# LargeDummyDevice register map
File version: 1.0
Registers are 32-bit, read-write, no defined reset value unless marked. A register's access mark holds for its fields unless they carry their own. Offsets are from the block's base; [hi:lo] are bit positions.

## PERIPHERAL_29
Base 0x4001C000
0x04 REG_1 — Register 1
  [33:29] FIELD_7, [28] FIELD_6, [23:22] FIELD_4, [20] FIELD_3, [17:14] FIELD_8, [16:12] FIELD_2, [10:8] FIELD_1, [12:8] FIELD_11, [10:7] FIELD_9, [9:6] FIELD_10, [1] FIELD_5
0x08 REG_2 — Register 2
  [30:28] FIELD_7, [27:25] FIELD_5, [24:21] FIELD_1, [22:20] FIELD_11, [20:16] FIELD_3, [15:11] FIELD_10, [10:7] FIELD_4, [10:6] FIELD_2, [6:5] FIELD_13, [3] FIELD_8, [7:3] FIELD_9, [5:1] FIELD_6, [5:1] FIELD_12
0x0C REG_3 — Register 3
  [31:28] FIELD_7, [28:27] FIELD_11, [30:26] FIELD_5, [22] FIELD_1, [23:22] FIELD_3, [25:21] FIELD_6, [25:21] FIELD_15, [20] FIELD_10, [19] FIELD_14, [21:17] FIELD_13, [20:16] FIELD_12, [9:7] FIELD_4, [9:6] FIELD_8, [5:3] FIELD_9, [5:2] FIELD_2
0x10 REG_4 — Register 4
  [29] FIELD_10, [29:28] FIELD_8, [29:25] FIELD_13, [27:23] FIELD_16, [21] FIELD_2, [23:20] FIELD_3, [21:19] FIELD_15, [17] FIELD_14, [21:17] FIELD_17, [16:13] FIELD_21, [13:12] FIELD_5, [14:10] FIELD_1, [10] FIELD_7, [9:8] FIELD_19, [11:8] FIELD_20, [11:7] FIELD_6, [9:7] FIELD_22, [8:5] FIELD_9, [3] FIELD_12, [3:0] FIELD_4, [4:0] FIELD_11, [2:0] FIELD_18
0x14 REG_5 — Register 5
  [33:31] FIELD_2, [10:6] FIELD_1, [2:1] FIELD_3
0x18 REG_6 — Register 6
  [33:30] FIELD_21, [30:28] FIELD_11, [30:27] FIELD_2, [27] FIELD_7, [29:25] FIELD_4, [28:25] FIELD_13, [28:25] FIELD_17, [25:22] FIELD_27, [23:21] FIELD_8, [25:21] FIELD_14, [21:20] FIELD_10, [22:20] FIELD_12, [22:19] FIELD_3, [19:18] FIELD_18, [22:18] FIELD_23, [17:16] FIELD_31, [15:14] FIELD_6, [16:12] FIELD_19, [16:12] FIELD_24, [11] FIELD_16, [13:10] FIELD_15, [12:10] FIELD_28, [12:9] FIELD_20, [13:9] FIELD_26, [5] FIELD_25, [5] FIELD_29, [4] FIELD_1, [6:4] FIELD_9, [4] FIELD_30, [4:3] FIELD_22, [4:2] FIELD_5
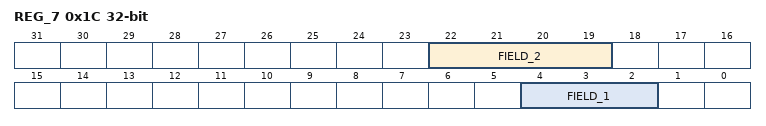
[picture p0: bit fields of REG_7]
0x1C REG_7 — Register 7
  [22:19] FIELD_2, [4:2] FIELD_1
0x20 REG_8 — Register 8
  [33:31] FIELD_10, [33:30] FIELD_16, [27] FIELD_1, [31:27] FIELD_4, [28:27] FIELD_25, [27:25] FIELD_3, [29:25] FIELD_24, [28:24] FIELD_5, [25:23] FIELD_9, [22] FIELD_6, [23:22] FIELD_17, [23:20] FIELD_15, [21:18] FIELD_14, [21:18] FIELD_23, [18:17] FIELD_11, [18:17] FIELD_21, [21:17] FIELD_22, [14:12] FIELD_8, [11] FIELD_7, [12:11] FIELD_18, [11:10] FIELD_20, [9:6] FIELD_13, [7:4] FIELD_12, [2:1] FIELD_2, [3:0] FIELD_19

## PERIPHERAL_35
Base 0x40022000
0x04 REG_1 — Register 1
  [30:29] FIELD_8, [28:27] FIELD_1, [31:27] FIELD_2, [29:27] FIELD_10, [26:25] FIELD_14, [28:24] FIELD_4, [25:23] FIELD_12, [23:20] FIELD_7, [22:20] FIELD_9, [21:18] FIELD_15, [17:14] FIELD_13, [12] FIELD_6, [13:11] FIELD_11, [6] FIELD_5, [5] FIELD_3
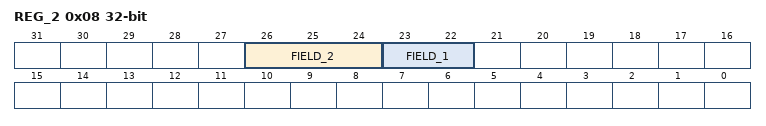
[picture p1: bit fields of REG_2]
0x08 REG_2 — Register 2
  [31:30] FIELD_8, [20:18] FIELD_2, [19:18] FIELD_5, [10:9] FIELD_4, [12:9] FIELD_11, [8] FIELD_1, [10:8] FIELD_9, [9:7] FIELD_7, [10:6] FIELD_6, [8:4] FIELD_10, [3] FIELD_3
0x0C REG_3 — Register 3
  [34:31] FIELD_3, [29] FIELD_2, [27:24] FIELD_12, [26:22] FIELD_4, [21:18] FIELD_8, [14:13] FIELD_13, [13:11] FIELD_7, [10:9] FIELD_5, [7:6] FIELD_11, [3:2] FIELD_1, [4:1] FIELD_6, [5:1] FIELD_9, [3:1] FIELD_10
0x10 REG_4 — Register 4
  [34:31] FIELD_3, [32:31] FIELD_19, [30] FIELD_4, [32:29] FIELD_10, [31:28] FIELD_18, [29:28] FIELD_20, [28:25] FIELD_17, [22] FIELD_6, [26:22] FIELD_7, [20] FIELD_5, [22:18] FIELD_9, [22:18] FIELD_12, [17] FIELD_8, [20:16] FIELD_16, [18:16] FIELD_22, [19:15] FIELD_1, [17:15] FIELD_2, [11:9] FIELD_14, [6] FIELD_13, [8:6] FIELD_21, [9:5] FIELD_15, [1] FIELD_11
0x14 REG_5 — Register 5
  [29:27] FIELD_4, [24] FIELD_5, [23:20] FIELD_8, [18] FIELD_1, [22:18] FIELD_2, [21:18] FIELD_3, [20:16] FIELD_10, [15] FIELD_7, [9] FIELD_9, [9:5] FIELD_11, [1:0] FIELD_6

## PERIPHERAL_36
Base 0x40023000
0x04 REG_1 — Register 1
  [24] FIELD_2, [28:24] FIELD_6, [23:21] FIELD_7, [14:12] FIELD_5, [8] FIELD_1, [9:7] FIELD_4, [2] FIELD_3
0x08 REG_2 — Register 2
  [26:24] FIELD_2, [23:22] FIELD_1
0x0C REG_3 — Register 3
  [33:31] FIELD_11, [33:31] FIELD_21, [30] FIELD_3, [31:30] FIELD_19, [28] FIELD_10, [32:28] FIELD_13, [30:27] FIELD_2, [30:27] FIELD_6, [25:21] FIELD_4, [22:20] FIELD_5, [24:20] FIELD_9, [22:18] FIELD_8, [13] FIELD_7, [16:13] FIELD_17, [11] FIELD_12, [10] FIELD_1, [12:10] FIELD_20, [9] FIELD_16, [6:5] FIELD_14, [8:4] FIELD_18, [6:2] FIELD_15
0x10 REG_4 — Register 4
  [31] FIELD_3, [28] FIELD_6, [31:28] FIELD_17, [28:27] FIELD_12, [28:27] FIELD_19, [27:24] FIELD_7, [26:24] FIELD_10, [28:24] FIELD_11, [27:24] FIELD_14, [23:20] FIELD_4, [21:20] FIELD_5, [18] FIELD_2, [19:16] FIELD_18, [17:15] FIELD_15, [15:13] FIELD_20, [14:11] FIELD_1, [12:11] FIELD_16, [11:9] FIELD_9, [9] FIELD_13, [9:5] FIELD_8
0x14 REG_5 — Register 5
  [32:30] FIELD_1, [29] FIELD_10, [22:18] FIELD_2, [18:16] FIELD_9, [13] FIELD_5, [13:9] FIELD_4, [11:9] FIELD_6, [10:7] FIELD_8, [9:6] FIELD_7, [1] FIELD_3
0x18 REG_6 — Register 6
  [31:28] FIELD_18, [29:28] FIELD_29, [28:27] FIELD_2, [29:27] FIELD_13, [31:27] FIELD_17, [30:26] FIELD_21, [28:25] FIELD_23, [29:25] FIELD_32, [25:23] FIELD_19, [23:22] FIELD_14, [24:22] FIELD_27, [23:20] FIELD_1, [22:20] FIELD_28, [19] FIELD_5, [20:19] FIELD_16, [19:16] FIELD_9, [16:14] FIELD_10, [16:13] FIELD_6, [15:12] FIELD_7, [12:11] FIELD_8, [14:11] FIELD_24, [14:11] FIELD_26, [12:9] FIELD_4, [9:7] FIELD_3, [11:7] FIELD_20, [9:6] FIELD_25, [8:5] FIELD_11, [6:5] FIELD_15, [7:4] FIELD_12, [4:3] FIELD_30, [6:3] FIELD_31, [1] FIELD_22
0x1C REG_7 — Register 7
  [31] FIELD_13, [30] FIELD_4, [29] FIELD_3, [29:28] FIELD_12, [30:26] FIELD_9, [26] FIELD_11, [26] FIELD_14, [27:23] FIELD_8, [25:23] FIELD_17, [25:22] FIELD_7, [22:21] FIELD_1, [22:21] FIELD_2, [21] FIELD_15, [24:20] FIELD_16, [11:9] FIELD_6, [8:7] FIELD_5, [6:3] FIELD_10
0x20 REG_8 — Register 8
  [33:30] FIELD_4, [33:30] FIELD_11, [32:30] FIELD_21, [29] FIELD_20, [30:27] FIELD_18, [25:24] FIELD_7, [24] FIELD_16, [25:23] FIELD_14, [25:23] FIELD_15, [24:22] FIELD_12, [24:21] FIELD_13, [25:21] FIELD_19, [21:20] FIELD_9, [21:17] FIELD_2, [21:17] FIELD_5, [20:17] FIELD_22, [15] FIELD_10, [11:8] FIELD_3, [9:8] FIELD_8, [10:8] FIELD_17, [4] FIELD_6, [0] FIELD_1
0x24 REG_9 — Register 9
  [31] FIELD_2, [31:30] FIELD_3, [27:26] FIELD_11, [23:22] FIELD_19, [24:21] FIELD_17, [22:18] FIELD_7, [21:18] FIELD_21, [19:16] FIELD_14, [17:15] FIELD_16, [16:14] FIELD_6, [15:11] FIELD_9, [13:10] FIELD_1, [13:10] FIELD_12, [13:10] FIELD_22, [8:6] FIELD_15, [7:6] FIELD_18, [7:5] FIELD_5, [2:1] FIELD_4, [4:1] FIELD_8, [3:1] FIELD_13, [1:0] FIELD_10, [4:0] FIELD_20, [3:0] FIELD_23
